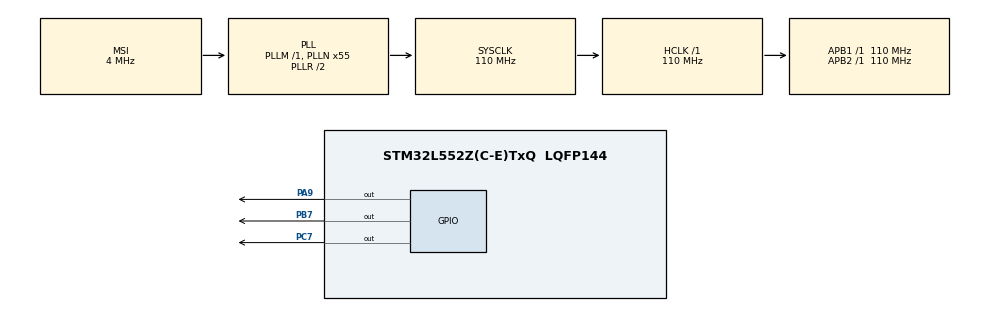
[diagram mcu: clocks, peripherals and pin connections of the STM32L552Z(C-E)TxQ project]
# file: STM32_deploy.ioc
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Dma.DMA_GENERATOR0.0.Channel_PRIV_NPRIV=DMA_CHANNEL_NPRIV_DISABLE
Dma.DMA_GENERATOR0.0.Direction=DMA_PERIPH_TO_MEMORY
Dma.DMA_GENERATOR0.0.EventEnable=DISABLE
Dma.DMA_GENERATOR0.0.Instance=DMA1_Channel2
Dma.DMA_GENERATOR0.0.MemDataAlignment=DMA_MDATAALIGN_WORD
Dma.DMA_GENERATOR0.0.MemInc=DMA_MINC_ENABLE
Dma.DMA_GENERATOR0.0.Mode=DMA_CIRCULAR
Dma.DMA_GENERATOR0.0.PeriphDataAlignment=DMA_PDATAALIGN_WORD
Dma.DMA_GENERATOR0.0.PeriphInc=DMA_PINC_DISABLE
Dma.DMA_GENERATOR0.0.Polarity=HAL_DMAMUX_REQ_GEN_RISING
Dma.DMA_GENERATOR0.0.Priority=DMA_PRIORITY_HIGH
Dma.DMA_GENERATOR0.0.RequestNumber=1
Dma.DMA_GENERATOR0.0.SignalID=NONE
Dma.DMA_GENERATOR0.0.SyncEnable=DISABLE
Dma.DMA_GENERATOR0.0.SyncPolarity=HAL_DMAMUX_SYNC_NO_EVENT
Dma.DMA_GENERATOR0.0.SyncRequestNumber=1
Dma.DMA_GENERATOR0.0.SyncSignalID=NONE
Dma.Request0=DMA_GENERATOR0
Mcu.Family=STM32L5
Mcu.Name=STM32L552Z(C-E)TxQ
Mcu.Package=LQFP144
Mcu.TrustZone=disable
NUCLEO-L552ZE-Q.BUTTON=1
NUCLEO-L552ZE-Q.LD1=true
NUCLEO-L552ZE-Q.LD2=true
NUCLEO-L552ZE-Q.LD3=true
NUCLEO-L552ZE-Q.VCP=true
NVIC.DMA1_Channel2_IRQn=true\:0\:0\:false\:false\:true\:false\:true\:true
NVIC.DMAMUX1_IRQn=true\:0\:0\:false\:false\:true\:false\:true\:true
NVIC.EXTI13_IRQn=true\:0\:0\:false\:false\:true\:false\:true\:true
NVIC.PriorityGroup=NVIC_PRIORITYGROUP_3
PA13\ (JTMS/SWDIO).Mode=Serial_Wire
PA13\ (JTMS/SWDIO).Signal=DEBUG_JTMS-SWDIO
PA14\ (JTCK/SWCLK).Mode=Serial_Wire
PA14\ (JTCK/SWCLK).Signal=DEBUG_JTCK-SWCLK
PA9.Signal=GPIO_Output
PB3\ (JTDO/TRACESWO).Signal=DEBUG_JTDO-SWO
PB7.Signal=GPIO_Output
PC13.Signal=PWR_WKUP2
PC14-OSC32_IN\ (PC14).Mode=LSE-External-Oscillator
PC14-OSC32_IN\ (PC14).Signal=RCC_OSC32_IN
PC15-OSC32_OUT\ (PC15).Mode=LSE-External-Oscillator
PC15-OSC32_OUT\ (PC15).Signal=RCC_OSC32_OUT
PC7.Signal=GPIO_Output
PG7.Signal=LPUART1_TX
PG8.Signal=LPUART1_RX
PH0-OSC_IN\ (PH0).Mode=HSE-External-Oscillator
PH0-OSC_IN\ (PH0).Signal=RCC_OSC_IN
PH1-OSC_OUT\ (PH1).Mode=HSE-External-Oscillator
PH1-OSC_OUT\ (PH1).Signal=RCC_OSC_OUT
ProjectManager.HeapSize=0x200
ProjectManager.StackSize=0x400
ProjectManager.TargetToolchain=CMake
RCC.ADCCLockSelection=RCC_ADCCLKSOURCE_SYSCLK
RCC.ADCFreq_Value=110000000
RCC.AHBFreq_Value=110000000
RCC.APB1Freq_Value=110000000
RCC.APB1TimFreq_Value=110000000
RCC.APB2Freq_Value=110000000
RCC.APB2TimFreq_Value=110000000
RCC.CK48CLockSelection=RCC_USBCLKSOURCE_HSI48
RCC.CortexFreq_Value=110000000
RCC.HCLKFreq_Value=110000000
RCC.HSE_VALUE=8000000
RCC.HSI48_VALUE=48000000
RCC.HSI_VALUE=16000000
RCC.MSI_VALUE=4000000
RCC.PLLN=55
RCC.PLLSAI1N=24
RCC.RTCClockSelection=RCC_RTCCLKSOURCE_LSE
RCC.SYSCLKFreq_VALUE=110000000
RCC.SYSCLKSource=RCC_SYSCLKSOURCE_PLLCLK
RCC.USBFreq_Value=48000000
RCC.VCOOutputFreq_Value=220000000
VP_ICACHE_VS_ICACHE.Mode=DirectMappedCache
VP_NUCLEO-L552ZE-Q_VS_BSP_COMMON.Mode=COMMON
VP_PWR_VS_DBSignals.Mode=DisableDeadBatterySignals
VP_PWR_VS_SECSignals.Mode=Security/Privilege
board=NUCLEO-L552ZE-Q

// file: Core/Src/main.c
/* USER CODE BEGIN Header */
/**
  ******************************************************************************
  * @file           : main.c
  * @brief          : Main program body
  ******************************************************************************
  * @attention
  *
  * Copyright (c) 2025 STMicroelectronics.
  * All rights reserved.
  *
  * This software is licensed under terms that can be found in the LICENSE file
  * in the root directory of this software component.
  * If no LICENSE file comes with this software, it is provided AS-IS.
  *
  ******************************************************************************
  */
/* USER CODE END Header */
#include "main.h"

/* USER CODE BEGIN Includes */
#include "stm32_deploy_app.h"
/* USER CODE END Includes */

void SystemClock_Config(void);
static void MX_GPIO_Init(void);
static void MX_ICACHE_Init(void);

int main(void)
{

  /* MCU Configuration--------------------------------------------------------*/

  /* Reset of all peripherals, Initializes the Flash interface and the Systick. */
  HAL_Init();

  /* Configure the system clock */
  SystemClock_Config();

  /* Initialize all configured peripherals */
  MX_GPIO_Init();
  MX_ICACHE_Init();

  /* USER CODE BEGIN 2 */
  if (STM32DeployApp_Run() != 0)
  {
    Error_Handler();
  }
  /* USER CODE END 2 */

  /* Infinite loop */
  /* USER CODE BEGIN WHILE */
  while (1)
  {
    __WFI();
    /* USER CODE END WHILE */
  }
}

void SystemClock_Config(void)
{
  RCC_OscInitTypeDef RCC_OscInitStruct = {0};
  RCC_ClkInitTypeDef RCC_ClkInitStruct = {0};

  /** Configure the main internal regulator output voltage
  */
  if (HAL_PWREx_ControlVoltageScaling(PWR_REGULATOR_VOLTAGE_SCALE0) != HAL_OK)
  {
    Error_Handler();
  }

  /** Initializes the RCC Oscillators according to the specified parameters
  * in the RCC_OscInitTypeDef structure.
  */
  RCC_OscInitStruct.OscillatorType = RCC_OSCILLATORTYPE_MSI;
  RCC_OscInitStruct.MSIState = RCC_MSI_ON;
  RCC_OscInitStruct.MSICalibrationValue = RCC_MSICALIBRATION_DEFAULT;
  RCC_OscInitStruct.MSIClockRange = RCC_MSIRANGE_6;
  RCC_OscInitStruct.PLL.PLLState = RCC_PLL_ON;
  RCC_OscInitStruct.PLL.PLLSource = RCC_PLLSOURCE_MSI;
  RCC_OscInitStruct.PLL.PLLM = 1;
  RCC_OscInitStruct.PLL.PLLN = 55;
  RCC_OscInitStruct.PLL.PLLP = RCC_PLLP_DIV7;
  RCC_OscInitStruct.PLL.PLLQ = RCC_PLLQ_DIV2;
  RCC_OscInitStruct.PLL.PLLR = RCC_PLLR_DIV2;
  if (HAL_RCC_OscConfig(&RCC_OscInitStruct) != HAL_OK)
  {
    Error_Handler();
  }

  /** Initializes the CPU, AHB and APB buses clocks
  */
  RCC_ClkInitStruct.ClockType = RCC_CLOCKTYPE_HCLK|RCC_CLOCKTYPE_SYSCLK
                              |RCC_CLOCKTYPE_PCLK1|RCC_CLOCKTYPE_PCLK2;
  RCC_ClkInitStruct.SYSCLKSource = RCC_SYSCLKSOURCE_PLLCLK;
  RCC_ClkInitStruct.AHBCLKDivider = RCC_SYSCLK_DIV1;
  RCC_ClkInitStruct.APB1CLKDivider = RCC_HCLK_DIV1;
  RCC_ClkInitStruct.APB2CLKDivider = RCC_HCLK_DIV1;

  if (HAL_RCC_ClockConfig(&RCC_ClkInitStruct, FLASH_LATENCY_5) != HAL_OK)
  {
    Error_Handler();
  }
}

static void MX_ICACHE_Init(void)
{

  /** Enable instruction cache in 1-way (direct mapped cache)
  */
  if (HAL_ICACHE_ConfigAssociativityMode(ICACHE_1WAY) != HAL_OK)
  {
    Error_Handler();
  }
  if (HAL_ICACHE_Enable() != HAL_OK)
  {
    Error_Handler();
  }

}

static void MX_GPIO_Init(void)
{

  /* GPIO Ports Clock Enable */
  __HAL_RCC_GPIOC_CLK_ENABLE();
  __HAL_RCC_GPIOF_CLK_ENABLE();
  __HAL_RCC_GPIOH_CLK_ENABLE();
  __HAL_RCC_GPIOB_CLK_ENABLE();
  __HAL_RCC_GPIOA_CLK_ENABLE();

}

void Error_Handler(void)
{
  __disable_irq();
  while (1)
  {
  }
}
